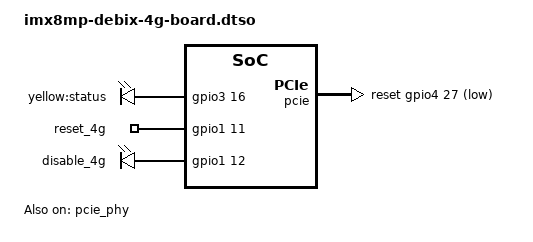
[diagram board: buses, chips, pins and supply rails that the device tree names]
// SPDX-License-Identifier: (GPL-2.0+ OR MIT)
/*
 * Copyright 2019 NXP
 */

/dts-v1/;
/plugin/;
#include "../../freescale/imx8mp-pinfunc.h"
#include <dt-bindings/clock/imx8mp-clock.h>
#include <dt-bindings/power/imx8mp-power.h>
#include <dt-bindings/reset/imx8mp-reset.h>
#include <dt-bindings/power/imx8mp-power.h>
#include <dt-bindings/gpio/gpio.h>
#include <dt-bindings/input/input.h>
#include <dt-bindings/interrupt-controller/arm-gic.h>
#include <dt-bindings/thermal/thermal.h>
#include <dt-bindings/usb/pd.h>
#include <dt-bindings/phy/phy-imx8-pcie.h>

&{/} {
	gpio_leds: gpio-leds {
		compatible = "gpio-leds";
		pinctrl-names = "default";
		pinctrl-0 = <&pinctrl_gpio_led>;

		status {
			label = "yellow:status";
			gpios = <&gpio3 16 GPIO_ACTIVE_HIGH>;
			default-state = "on";
		};
		
		reset_4g {
			label = "reset_4g";
			gpios = <&gpio1 11 GPIO_ACTIVE_HIGH>;
			default-state = "off";
		};
		disable_4g {
			label = "disable_4g";
			gpios = <&gpio1 12 GPIO_ACTIVE_HIGH>;
			default-state = "off";
		};
	};

};

&pcie {
	pinctrl-names = "default";
	pinctrl-0 = <&pinctrl_pcie>;
	//disable-gpio = <&gpio2 6 GPIO_ACTIVE_LOW>;
	reset-gpio = <&gpio4 27 GPIO_ACTIVE_LOW>;
	vdd2v5_en = <&gpio5 3 GPIO_ACTIVE_HIGH>;
	vdd1v1_en = <&gpio5 4 GPIO_ACTIVE_HIGH>;
	vdd3v3_en = <&gpio1 13 GPIO_ACTIVE_HIGH>;

	clocks = <&clk IMX8MP_CLK_HSIO_ROOT>,
		 <&clk IMX8MP_CLK_PCIE_ROOT>,
		 <&clk IMX8MP_CLK_HSIO_AXI>;
	clock-names = "pcie", "pcie_aux", "pcie_bus";
	assigned-clocks = <&clk IMX8MP_CLK_PCIE_AUX>;
	assigned-clock-rates = <10000000>;
	assigned-clock-parents = <&clk IMX8MP_SYS_PLL2_50M>;
	/delete-property/ vpcie-supply;
	ext_osc = <0>;
	fsl,max-link-speed = <2>;
	status = "okay";
};

&pcie_phy {
	ext_osc = <0>;
	fsl,refclk-pad-mode = <IMX8_PCIE_REFCLK_PAD_OUTPUT>;
	clocks = <&hsio_blk_ctrl>;
	clock-names = "ref";
	status = "okay";
};

&iomuxc {
	pinctrl_gpio_led: gpioledgrp {
		fsl,pins = <
			MX8MP_IOMUXC_NAND_READY_B__GPIO3_IO16	0x140
			MX8MP_IOMUXC_GPIO1_IO11__GPIO1_IO11	0x19
			MX8MP_IOMUXC_GPIO1_IO12__GPIO1_IO12	0x19
		>;
	};

	pinctrl_pcie: pciegrp {
		fsl,pins = <
			//pcie rst
			MX8MP_IOMUXC_SAI2_MCLK__GPIO4_IO27  0x41
			//pcie clkreq
			//MX8MP_IOMUXC_SAI2_RXC__GPIO4_IO22   0x41
			//pcie wake
			MX8MP_IOMUXC_SAI2_RXFS__GPIO4_IO21  0x41

			//vdd2v5_en
			MX8MP_IOMUXC_SPDIF_TX__GPIO5_IO03  0x1f	
			//vdd1v1_en
			MX8MP_IOMUXC_SPDIF_RX__GPIO5_IO04  0x1f
			//vdd3v3_en
			MX8MP_IOMUXC_GPIO1_IO13__GPIO1_IO13 0x1f
		//MX8MP_IOMUXC_I2C4_SCL__PCIE_CLKREQ_B		0x60 /* open drain, pull up */
		//MX8MP_IOMUXC_SD1_DATA4__GPIO2_IO06		0x40
		//	MX8MP_IOMUXC_SD1_DATA5__GPIO2_IO07		0x40
		//	MX8MP_IOMUXC_I2C4_SDA__GPIO5_IO21		0x1c4
		>;
	};

};

